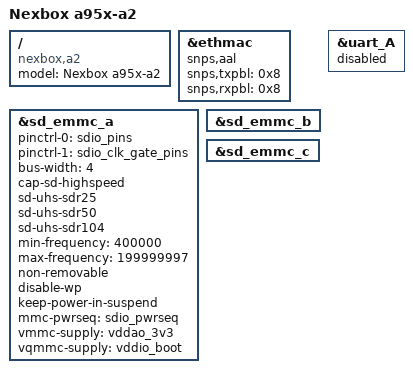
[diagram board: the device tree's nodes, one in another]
// SPDX-License-Identifier: (GPL-2.0+ OR MIT)
/*
 * Copyright (c) 2022 by sibondt
 */

/dts-v1/;

#include "meson-gxm-q200.dts"

/ {
	compatible = "nexbox,a2", "amlogic,s912", "amlogic,meson-gxm";
	model = "Nexbox a95x-a2";
};

&ethmac {
	snps,aal;
	snps,txpbl = <0x8>;
	snps,rxpbl = <0x8>;
};

/* Wireless SDIO Module */
&sd_emmc_a {
	status = "okay";
	pinctrl-0 = <&sdio_pins>;
	pinctrl-1 = <&sdio_clk_gate_pins>;
	pinctrl-names = "default", "clk-gate";
	#address-cells = <1>;
	#size-cells = <0>;

	bus-width = <4>;
	cap-sd-highspeed;
	sd-uhs-sdr25;
	sd-uhs-sdr50;
	sd-uhs-sdr104;
	min-frequency = <400000>;
	max-frequency = <199999997>;

	non-removable;
	disable-wp;

	/* WiFi firmware requires power to be kept while in suspend */
	keep-power-in-suspend;

	mmc-pwrseq = <&sdio_pwrseq>;

	vmmc-supply = <&vddao_3v3>;
	vqmmc-supply = <&vddio_boot>;
};

&sd_emmc_b {
        status = "okay";
};

&sd_emmc_c {
        status = "okay";
};

&uart_A {
	status = "disabled";
};
